# STM32F051x8 register map
File version: 1.0
Registers are 32-bit, read-write, reset 0x0 unless marked. A register's access mark holds for its fields unless they carry their own. Offsets are from the block's base; [hi:lo] are bit positions; {n}, {i} and the like mark numbered series.

## DAC — Digital to Analog Converter
Base 0x40007400
Same registers: DAC1 0x40007400 (alternate view of DAC)
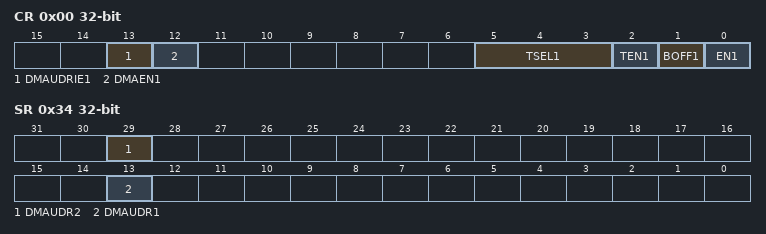
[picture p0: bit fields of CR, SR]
0x00 CR — DAC control register
  [13] DMAUDRIE1 — DAC channel1 DMA Underrun Interrupt enable
  [12] DMAEN1 — DAC channel1 DMA enable
  [5:3] TSEL1 — TSEL1[2:0] (DAC channel1 Trigger selection)
  [2] TEN1 — DAC channel1 Trigger enable
  [1] BOFF1 — DAC channel1 output buffer disable
  [0] EN1 — DAC channel1 enable
0x04 SWTRIGR — DAC software trigger register
  [0] SWTRIG1 — DAC channel1 software trigger
0x08 DHR12R1 — DAC channel1 12-bit right-aligned data holding register
  [11:0] DACC1DHR — DAC channel1 12-bit Right aligned data
0x0C DHR12L1 — DAC channel1 12-bit left aligned data holding register
  [15:4] DACC1DHR — DAC channel1 12-bit Left aligned data
0x10 DHR8R1 — DAC channel1 8-bit right aligned data holding register
  [7:0] DACC1DHR — DAC channel1 8-bit Right aligned data
0x2C DOR1 — DAC channel1 data output register
  [11:0] DACC1DOR — DAC channel1 data output
0x34 SR — DAC status register
  [29] DMAUDR2 — DAC channel2 DMA underrun flag
  [13] DMAUDR1 — DAC channel1 DMA underrun flag

## CEC — HDMI-CEC
Base 0x40007800
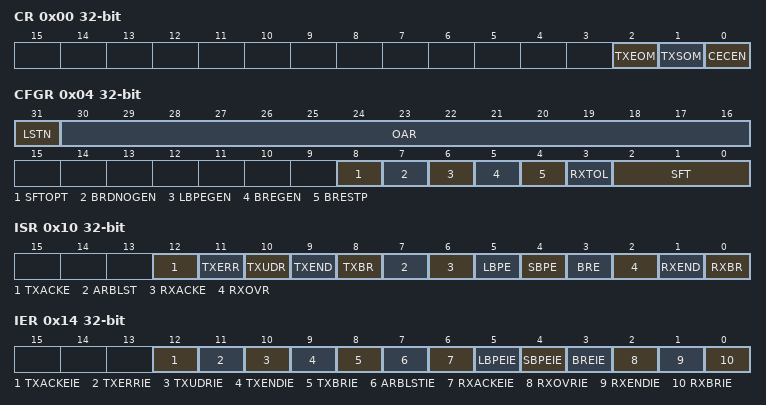
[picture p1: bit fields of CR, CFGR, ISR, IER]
0x00 CR — CEC control register
  [2] TXEOM — CEC Tx End Of Message
  [1] TXSOM — CEC Tx Start Of Message
  [0] CECEN — CEC Enable
0x04 CFGR — CEC configuration register
  [31] LSTN — CEC Listen mode
  [30:16] OAR — CEC Own Address
  [8] SFTOPT — CEC Signal Free Time optional
  [7] BRDNOGEN — CEC Broadcast No Error generation
  [6] LBPEGEN — CEC Long Bit Period Error gener
  [5] BREGEN — CEC Bit Rising Error generation
  [4] BRESTP — CEC Rx Stop
  [3] RXTOL — CEC Tolerance
  [2:0] SFT — CEC Signal Free Time
0x08 TXDR — CEC Tx data register
  [7:0] TXD — CEC Tx Data
0x0C RXDR — CEC Rx Data Register
  [7:0] RXD — CEC Rx Data
0x10 ISR — CEC Interrupt and Status Register
  [12] TXACKE — CEC Tx Missing Acknowledge
  [11] TXERR — CEC Tx-Error
  [10] TXUDR — CEC Tx-Buffer Underrun
  [9] TXEND — CEC End of Transmission
  [8] TXBR — CEC Tx Byte Request
  [7] ARBLST — CEC Arbitration Lost
  [6] RXACKE — CEC Rx Missing Acknowledge
  [5] LBPE — CEC Rx Long Bit period Error
  [4] SBPE — CEC Rx Short Bit period Error
  [3] BRE — CEC Rx Bit Rising Error
  [2] RXOVR — CEC Rx-Overrun
  [1] RXEND — CEC End Of Reception
  [0] RXBR — CEC Rx-Byte Received
0x14 IER — CEC interrupt enable register
  [12] TXACKEIE — CEC Tx Missing Acknowledge IT Enable
  [11] TXERRIE — CEC Tx-Error IT Enable
  [10] TXUDRIE — CEC Tx-Buffer Underrun IT Enable
  [9] TXENDIE — CEC End of Transmission IT Enable
  [8] TXBRIE — CEC Tx Byte Request IT Enable
  [7] ARBLSTIE — CEC Arbitration Lost IT Enable
  [6] RXACKEIE — CEC Rx Missing Acknowledge IT Enable
  [5] LBPEIE — CEC Rx Long Bit period Error IT Enable
  [4] SBPEIE — CEC Rx Short Bit period Error IT Enable
  [3] BREIE — CEC Rx Bit Rising Error IT Enable
  [2] RXOVRIE — CEC Rx-Overrun IT Enable
  [1] RXENDIE — CEC End Of Reception IT Enable
  [0] RXBRIE — CEC Rx-Byte Received IT Enable

## SYSCFG — SysTem Configuration
Base 0x40010000
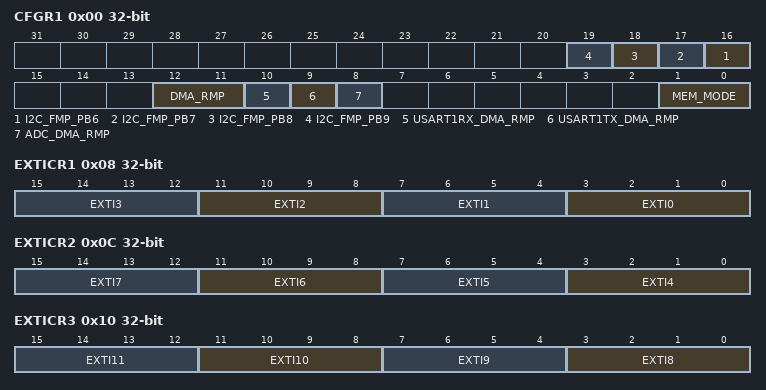
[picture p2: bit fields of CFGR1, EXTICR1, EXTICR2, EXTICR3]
0x00 CFGR1 — SYSCFG configuration register 1
  [n+10] I2C_FMP_PB{n} (n=6..9) — I2C PB{n} Fast mode plus
  [12:11] DMA_RMP — DMA remap mask
  [10] USART1RX_DMA_RMP — USART1 RX DMA remap
  [9] USART1TX_DMA_RMP — USART1 TX DMA remap
  [8] ADC_DMA_RMP — ADC DMA remap
    0=CH1 (ADC DMA request mapped on DMA channel 1U); 1=CH2 (ADC DMA request mapped on DMA channel 2U)
  [1:0] MEM_MODE — SYSCFG_Memory Remap Config
    0=FLASH (Main Flash memory mapped at 0x00000000); 1=SYSTEMFLASH (System Flash memory mapped at 0x00000000); 3=SRAM (Embedded SRAM mapped at 0x00000000)
0x08 EXTICR1 — SYSCFG external interrupt configuration register
  [4n+3:4n] EXTI{n} (n=0..3) — EXTI {n} configuration
0x0C EXTICR2 — SYSCFG external interrupt configuration register
  [4n-13:4n-16] EXTI{n} (n=4..7) — EXTI {n} configuration
0x10 EXTICR3 — SYSCFG external interrupt configuration register
  [4n-29:4n-32] EXTI{n} (n=8..11) — EXTI {n} configuration
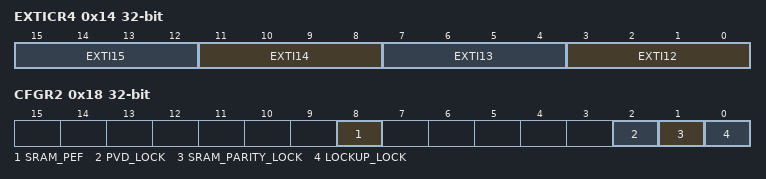
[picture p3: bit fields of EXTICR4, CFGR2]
0x14 EXTICR4 — SYSCFG external interrupt configuration register
  [4n-45:4n-48] EXTI{n} (n=12..15) — EXTI {n} configuration
0x18 CFGR2 — SYSCFG configuration register 2
  [8] SRAM_PEF — SRAM Parity error flag
  [2] PVD_LOCK — Enables and locks the PVD connection with Timer1 Break Input and also the PVD_EN and PVDSEL[2:0] bits of the Power Control Interface
  [1] SRAM_PARITY_LOCK — Enables and locks the SRAM_PARITY error signal with Break Input of TIMER1
  [0] LOCKUP_LOCK — Enables and locks the LOCKUP (Hardfault) output of CortexM0 with Break Input of TIMER1
